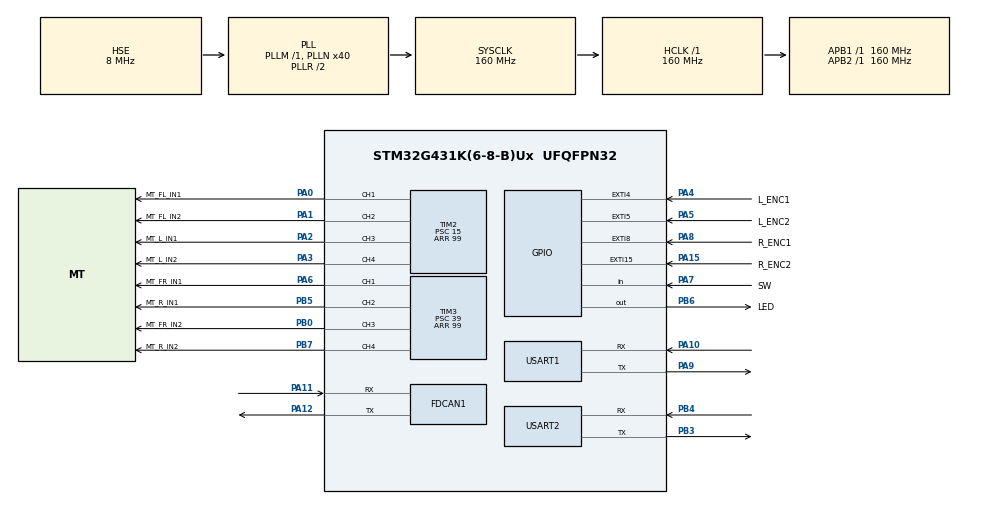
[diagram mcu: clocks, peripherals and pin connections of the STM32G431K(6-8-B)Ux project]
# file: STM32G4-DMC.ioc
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Dma.Request0=USART2_RX
Dma.Request1=USART1_RX
Dma.USART1_RX.1.Direction=DMA_PERIPH_TO_MEMORY
Dma.USART1_RX.1.EventEnable=DISABLE
Dma.USART1_RX.1.Instance=DMA1_Channel1
Dma.USART1_RX.1.MemDataAlignment=DMA_MDATAALIGN_BYTE
Dma.USART1_RX.1.MemInc=DMA_MINC_ENABLE
Dma.USART1_RX.1.Mode=DMA_NORMAL
Dma.USART1_RX.1.PeriphDataAlignment=DMA_PDATAALIGN_BYTE
Dma.USART1_RX.1.PeriphInc=DMA_PINC_DISABLE
Dma.USART1_RX.1.Polarity=HAL_DMAMUX_REQ_GEN_RISING
Dma.USART1_RX.1.Priority=DMA_PRIORITY_LOW
Dma.USART1_RX.1.RequestNumber=1
Dma.USART1_RX.1.SignalID=NONE
Dma.USART1_RX.1.SyncEnable=DISABLE
Dma.USART1_RX.1.SyncPolarity=HAL_DMAMUX_SYNC_NO_EVENT
Dma.USART1_RX.1.SyncRequestNumber=1
Dma.USART1_RX.1.SyncSignalID=NONE
Dma.USART2_RX.0.Direction=DMA_PERIPH_TO_MEMORY
Dma.USART2_RX.0.EventEnable=DISABLE
Dma.USART2_RX.0.Instance=DMA1_Channel2
Dma.USART2_RX.0.MemDataAlignment=DMA_MDATAALIGN_BYTE
Dma.USART2_RX.0.MemInc=DMA_MINC_ENABLE
Dma.USART2_RX.0.Mode=DMA_NORMAL
Dma.USART2_RX.0.PeriphDataAlignment=DMA_PDATAALIGN_BYTE
Dma.USART2_RX.0.PeriphInc=DMA_PINC_DISABLE
Dma.USART2_RX.0.Polarity=HAL_DMAMUX_REQ_GEN_RISING
Dma.USART2_RX.0.Priority=DMA_PRIORITY_LOW
Dma.USART2_RX.0.RequestNumber=1
Dma.USART2_RX.0.SignalID=NONE
Dma.USART2_RX.0.SyncEnable=DISABLE
Dma.USART2_RX.0.SyncPolarity=HAL_DMAMUX_SYNC_NO_EVENT
Dma.USART2_RX.0.SyncRequestNumber=1
Dma.USART2_RX.0.SyncSignalID=NONE
FDCAN1.CalculateBaudRateNominal=1000000
FDCAN1.CalculateTimeBitNominal=1000
FDCAN1.CalculateTimeQuantumNominal=200.0
Mcu.Family=STM32G4
Mcu.Name=STM32G431K(6-8-B)Ux
Mcu.Package=UFQFPN32
NVIC.EXTI15_10_IRQn=true\:0\:0\:false\:false\:true\:true\:true\:true
NVIC.EXTI4_IRQn=true\:0\:0\:true\:false\:true\:true\:true\:true
NVIC.EXTI9_5_IRQn=true\:0\:0\:true\:false\:true\:true\:true\:true
NVIC.FDCAN1_IT0_IRQn=true\:0\:0\:false\:false\:true\:true\:true\:true
NVIC.FDCAN1_IT1_IRQn=true\:0\:0\:false\:false\:true\:true\:true\:true
NVIC.PriorityGroup=NVIC_PRIORITYGROUP_4
PA0.GPIO_Label=MT_FL_IN1
PA0.GPIO_PuPd=GPIO_NOPULL
PA0.GPIO_Speed=GPIO_SPEED_FREQ_MEDIUM
PA0.Signal=S_TIM2_CH1
PA1.GPIO_Label=MT_FL_IN2
PA1.GPIO_PuPd=GPIO_NOPULL
PA1.GPIO_Speed=GPIO_SPEED_FREQ_MEDIUM
PA1.Signal=S_TIM2_CH2
PA10.Mode=Asynchronous
PA10.Signal=USART1_RX
PA11.Mode=FDCAN_Activate
PA11.Signal=FDCAN1_RX
PA12.Mode=FDCAN_Activate
PA12.Signal=FDCAN1_TX
PA13.Mode=Serial_Wire
PA13.Signal=SYS_JTMS-SWDIO
PA14.Mode=Serial_Wire
PA14.Signal=SYS_JTCK-SWCLK
PA15.GPIO_Label=R_ENC2
PA15.GPIO_ModeDefaultEXTI=GPIO_MODE_IT_RISING_FALLING
PA15.Signal=GPXTI15
PA2.GPIO_Label=MT_L_IN1
PA2.GPIO_PuPd=GPIO_NOPULL
PA2.GPIO_Speed=GPIO_SPEED_FREQ_MEDIUM
PA2.Signal=S_TIM2_CH3
PA3.GPIO_Label=MT_L_IN2
PA3.GPIO_PuPd=GPIO_NOPULL
PA3.GPIO_Speed=GPIO_SPEED_FREQ_MEDIUM
PA3.Signal=S_TIM2_CH4
PA4.GPIO_Label=L_ENC1
PA4.GPIO_ModeDefaultEXTI=GPIO_MODE_IT_RISING_FALLING
PA4.GPIO_PuPd=GPIO_NOPULL
PA4.Signal=GPXTI4
PA5.GPIO_Label=L_ENC2
PA5.GPIO_ModeDefaultEXTI=GPIO_MODE_IT_RISING_FALLING
PA5.Signal=GPXTI5
PA6.GPIO_Label=MT_FR_IN1
PA6.GPIO_PuPd=GPIO_NOPULL
PA6.GPIO_Speed=GPIO_SPEED_FREQ_MEDIUM
PA6.Signal=S_TIM3_CH1
PA7.GPIO_Label=SW
PA7.GPIO_PuPd=GPIO_NOPULL
PA7.Signal=GPIO_Input
PA8.GPIO_Label=R_ENC1
PA8.GPIO_ModeDefaultEXTI=GPIO_MODE_IT_RISING_FALLING
PA8.GPIO_PuPd=GPIO_NOPULL
PA8.Signal=GPXTI8
PA9.Mode=Asynchronous
PA9.Signal=USART1_TX
PB0.GPIO_Label=MT_FR_IN2
PB0.GPIO_PuPd=GPIO_NOPULL
PB0.GPIO_Speed=GPIO_SPEED_FREQ_MEDIUM
PB0.Signal=S_TIM3_CH3
PB3.Mode=Asynchronous
PB3.Signal=USART2_TX
PB4.Mode=Asynchronous
PB4.Signal=USART2_RX
PB5.GPIO_Label=MT_R_IN1
PB5.GPIO_PuPd=GPIO_NOPULL
PB5.GPIO_Speed=GPIO_SPEED_FREQ_MEDIUM
PB5.Signal=S_TIM3_CH2
PB6.GPIO_Label=LED
PB6.Signal=GPIO_Output
PB7.GPIO_Label=MT_R_IN2
PB7.GPIO_PuPd=GPIO_NOPULL
PB7.GPIO_Speed=GPIO_SPEED_FREQ_MEDIUM
PB7.Signal=S_TIM3_CH4
PF0-OSC_IN.Mode=HSE-External-Oscillator
PF0-OSC_IN.Signal=RCC_OSC_IN
PF1-OSC_OUT.Mode=HSE-External-Oscillator
PF1-OSC_OUT.Signal=RCC_OSC_OUT
ProjectManager.HeapSize=0x200
ProjectManager.StackSize=0x400
ProjectManager.TargetToolchain=STM32CubeIDE
RCC.ADC12Freq_Value=160000000
RCC.AHBFreq_Value=160000000
RCC.APB1Freq_Value=160000000
RCC.APB1TimFreq_Value=160000000
RCC.APB2Freq_Value=160000000
RCC.APB2TimFreq_Value=160000000
RCC.CortexFreq_Value=160000000
RCC.EXTERNAL_CLOCK_VALUE=12288000
RCC.FDCANCLockSelection=RCC_FDCANCLKSOURCE_PLL
RCC.HCLKFreq_Value=160000000
RCC.HSE_VALUE=8000000
RCC.HSI48_VALUE=48000000
RCC.HSICalibrationValue=64
RCC.HSI_VALUE=16000000
RCC.LSE_VALUE=32768
RCC.PLLN=40
RCC.PLLQ=RCC_PLLQ_DIV4
RCC.PLLSourceVirtual=RCC_PLLSOURCE_HSE
RCC.SYSCLKFreq_VALUE=160000000
RCC.SYSCLKSource=RCC_SYSCLKSOURCE_PLLCLK
RCC.USBFreq_Value=80000000
RCC.VCOOutputFreq_Value=320000000
SH.S_TIM2_CH1.0=TIM2_CH1,PWM Generation1 CH1
SH.S_TIM2_CH2.0=TIM2_CH2,PWM Generation2 CH2
SH.S_TIM2_CH3.0=TIM2_CH3,PWM Generation3 CH3
SH.S_TIM2_CH4.0=TIM2_CH4,PWM Generation4 CH4
SH.S_TIM3_CH1.0=TIM3_CH1,PWM Generation1 CH1
SH.S_TIM3_CH2.0=TIM3_CH2,PWM Generation2 CH2
SH.S_TIM3_CH3.0=TIM3_CH3,PWM Generation3 CH3
SH.S_TIM3_CH4.0=TIM3_CH4,PWM Generation4 CH4
TIM2.Channel-PWM\ Generation1\ CH1=TIM_CHANNEL_1
TIM2.Channel-PWM\ Generation2\ CH2=TIM_CHANNEL_2
TIM2.Channel-PWM\ Generation3\ CH3=TIM_CHANNEL_3
TIM2.Channel-PWM\ Generation4\ CH4=TIM_CHANNEL_4
TIM2.OCMode_PWM-PWM\ Generation2\ CH2=TIM_OCMODE_PWM1
TIM2.PeriodNoDither=99
TIM2.Prescaler=15
TIM3.Channel-PWM\ Generation1\ CH1=TIM_CHANNEL_1
TIM3.Channel-PWM\ Generation2\ CH2=TIM_CHANNEL_2
TIM3.Channel-PWM\ Generation3\ CH3=TIM_CHANNEL_3
TIM3.Channel-PWM\ Generation4\ CH4=TIM_CHANNEL_4
TIM3.OCMode_PWM-PWM\ Generation1\ CH1=TIM_OCMODE_PWM1
TIM3.OCMode_PWM-PWM\ Generation2\ CH2=TIM_OCMODE_PWM1
TIM3.PeriodNoDither=99
TIM3.Prescaler=39
TIM3.PulseNoDither_1=0
TIM3.PulseNoDither_4=0
USART1.VirtualMode-Asynchronous=VM_ASYNC
USART2.VirtualMode-Asynchronous=VM_ASYNC
VP_SYS_VS_DBSignals.Mode=DisableDeadBatterySignals
VP_TIM2_VS_ClockSourceINT.Mode=Internal
VP_TIM3_VS_ClockSourceINT.Mode=Internal
board=custom

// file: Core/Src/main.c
/* USER CODE BEGIN Header */
/**
  ******************************************************************************
  * @file           : main.c
  * @brief          : Main program body
  ******************************************************************************
  * @attention
  *
  * Copyright (c) 2024 STMicroelectronics.
  * All rights reserved.
  *
  * This software is licensed under terms that can be found in the LICENSE file
  * in the root directory of this software component.
  * If no LICENSE file comes with this software, it is provided AS-IS.
  *
  ******************************************************************************
  */
/* USER CODE END Header */
#include "main.h"
#include "dma.h"
#include "fdcan.h"
#include "tim.h"
#include "usart.h"
#include "gpio.h"

/* USER CODE BEGIN Includes */
#include "ap.h"
/* USER CODE END Includes */

void SystemClock_Config(void);

int main(void)
{

  /* MCU Configuration--------------------------------------------------------*/

  /* Reset of all peripherals, Initializes the Flash interface and the Systick. */
  HAL_Init();

  /* Configure the system clock */
  SystemClock_Config();

  /* Initialize all configured peripherals */
  MX_GPIO_Init();
  MX_DMA_Init();
  MX_FDCAN1_Init();
  MX_USART1_UART_Init();
  MX_USART2_UART_Init();
  MX_TIM2_Init();
  MX_TIM3_Init();
  /* USER CODE BEGIN 2 */
  hwInit();
  apInit();
  apMain();

  /* USER CODE END 2 */

  /* Infinite loop */
  while (1)
  {

  }
}

void SystemClock_Config(void)
{
  RCC_OscInitTypeDef RCC_OscInitStruct = {0};
  RCC_ClkInitTypeDef RCC_ClkInitStruct = {0};

  /** Configure the main internal regulator output voltage
  */
  HAL_PWREx_ControlVoltageScaling(PWR_REGULATOR_VOLTAGE_SCALE1_BOOST);

  /** Initializes the RCC Oscillators according to the specified parameters
  * in the RCC_OscInitTypeDef structure.
  */
  RCC_OscInitStruct.OscillatorType = RCC_OSCILLATORTYPE_HSE;
  RCC_OscInitStruct.HSEState = RCC_HSE_ON;
  RCC_OscInitStruct.PLL.PLLState = RCC_PLL_ON;
  RCC_OscInitStruct.PLL.PLLSource = RCC_PLLSOURCE_HSE;
  RCC_OscInitStruct.PLL.PLLM = RCC_PLLM_DIV1;
  RCC_OscInitStruct.PLL.PLLN = 40;
  RCC_OscInitStruct.PLL.PLLP = RCC_PLLP_DIV2;
  RCC_OscInitStruct.PLL.PLLQ = RCC_PLLQ_DIV4;
  RCC_OscInitStruct.PLL.PLLR = RCC_PLLR_DIV2;
  if (HAL_RCC_OscConfig(&RCC_OscInitStruct) != HAL_OK)
  {
    Error_Handler();
  }

  /** Initializes the CPU, AHB and APB buses clocks
  */
  RCC_ClkInitStruct.ClockType = RCC_CLOCKTYPE_HCLK|RCC_CLOCKTYPE_SYSCLK
                              |RCC_CLOCKTYPE_PCLK1|RCC_CLOCKTYPE_PCLK2;
  RCC_ClkInitStruct.SYSCLKSource = RCC_SYSCLKSOURCE_PLLCLK;
  RCC_ClkInitStruct.AHBCLKDivider = RCC_SYSCLK_DIV1;
  RCC_ClkInitStruct.APB1CLKDivider = RCC_HCLK_DIV1;
  RCC_ClkInitStruct.APB2CLKDivider = RCC_HCLK_DIV1;

  if (HAL_RCC_ClockConfig(&RCC_ClkInitStruct, FLASH_LATENCY_4) != HAL_OK)
  {
    Error_Handler();
  }
}

/* USER CODE BEGIN 4 */

//volatile int32_t encoderCountL = 0;
//volatile int32_t encoderCountR = 0;
//
//void HAL_GPIO_EXTI_Callback(uint16_t GPIO_Pin)
//{
//    if (GPIO_Pin == L_ENC1_Pin) // MT_L
//    {
//        if (HAL_GPIO_ReadPin(GPIOA, L_ENC2_Pin) == GPIO_PIN_SET)
//        {
//            encoderCountL++; // CW
//        }
//        else
//        {
//            encoderCountL--; // CCW
//        }
//    }
//
//    if (GPIO_Pin == R_ENC1_Pin) // MT_R
//    {
//        if (HAL_GPIO_ReadPin(GPIOA, R_ENC2_Pin) == GPIO_PIN_SET)
//        {
//            encoderCountR++; // CW
//        }
//        else
//        {
//            encoderCountR--; // CCW
//        }
//    }
//}

/* USER CODE END 4 */

void Error_Handler(void)
{
  __disable_irq();
  while (1)
  {
  }
}
